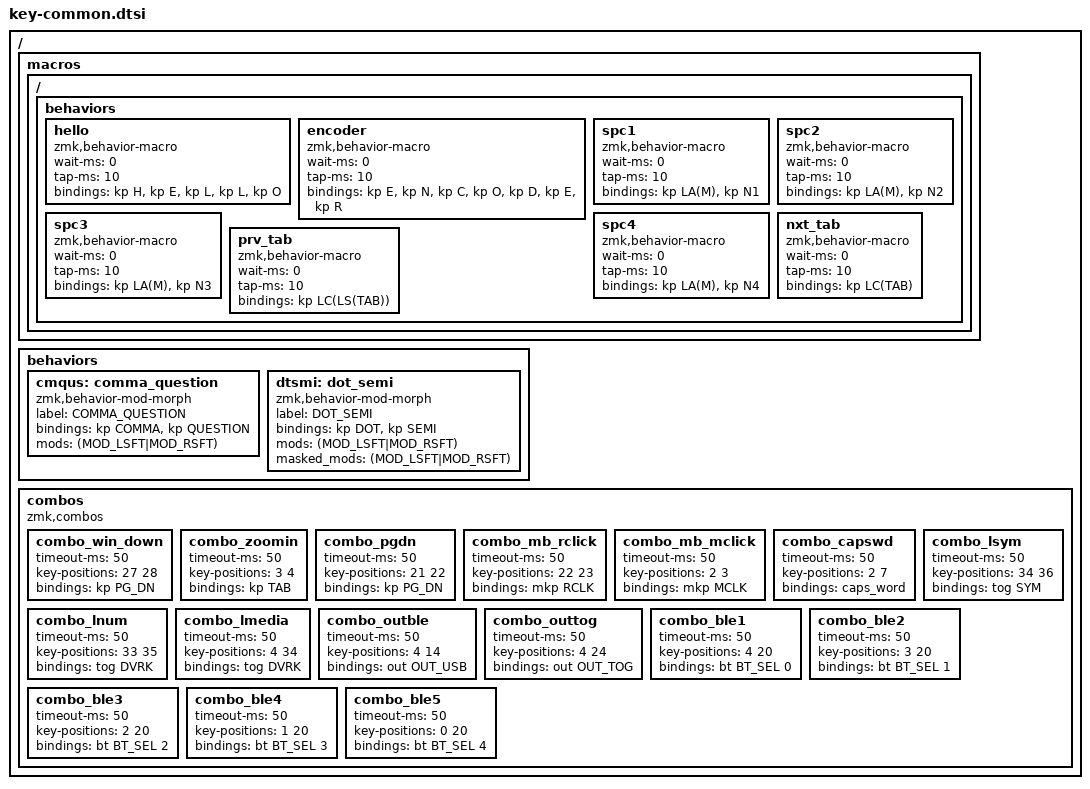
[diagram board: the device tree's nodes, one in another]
/ {
    // macros
    macros {
    ZMK_MACRO(hello,
        wait-ms = <0>;
        tap-ms  = <10>;
        bindings = <&kp H &kp E &kp L &kp L &kp O>;
    )

    ZMK_MACRO(encoder,
        wait-ms = <0>;
        tap-ms  = <10>;
        bindings = <&kp E &kp N &kp C &kp O &kp D &kp E &kp R>;
    )

    ZMK_MACRO(spc1,
        wait-ms = <0>;
        tap-ms  = <10>;
        bindings = <&kp LA(M) &kp N1>;
    )
    
    ZMK_MACRO(spc2,
        wait-ms = <0>;
        tap-ms  = <10>;
        bindings = <&kp LA(M) &kp N2>;
    )
    
    ZMK_MACRO(spc3,
        wait-ms = <0>;
        tap-ms  = <10>;
        bindings = <&kp LA(M) &kp N3>;
    )
   
    ZMK_MACRO(spc4,
        wait-ms = <0>;
        tap-ms  = <10>;
        bindings = <&kp LA(M) &kp N4>;
    )

    ZMK_MACRO(nxt_tab,
        wait-ms = <0>;
        tap-ms  = <10>;
        bindings = <&kp LC(TAB)>;
    )

    ZMK_MACRO(prv_tab,
        wait-ms = <0>;
        tap-ms  = <10>;
        bindings = <&kp LC(LS(TAB))>;
    )
    };

    // custom shift using mod-morph 
    behaviors {
      cmqus: comma_question {
        compatible = "zmk,behavior-mod-morph";
        label = "COMMA_QUESTION";
        #binding-cells = <0>;
        bindings = <&kp COMMA>, <&kp QUESTION>;
        mods = <(MOD_LSFT|MOD_RSFT)>;
      };

      dtsmi: dot_semi {
        compatible = "zmk,behavior-mod-morph";
        label = "DOT_SEMI";
        #binding-cells = <0>;
        bindings = <&kp DOT>, <&kp SEMI>;
        mods = <(MOD_LSFT|MOD_RSFT)>;
        masked_mods = <(MOD_LSFT|MOD_RSFT)>; // don't send shift
      };
    };

    // combos
     combos {
         compatible = "zmk,combos";
      
         combo_win_down {
            timeout-ms = <50>;
            key-positions = <27 28>;
            bindings = <&kp PG_DN>;
        };
        

        combo_zoomin {
            timeout-ms = <50>;
            key-positions = <3 4>;
            bindings = <&kp TAB>;
        };
 
        combo_pgdn {
            timeout-ms = <50>;
            key-positions = <21 22>;
            bindings = <&kp PG_DN>;
        };
 
        combo_mb_rclick {
            timeout-ms = <50>;
            key-positions = <22 23>;
            bindings = <&mkp RCLK>;
        };

         combo_mb_mclick {
            timeout-ms = <50>;
            key-positions = <2 3>;
            bindings = <&mkp MCLK>;
        };
 

        // others
        combo_capswd {
            timeout-ms = <50>;
            key-positions = <2 7>;
            bindings = <&caps_word>;
        };

        combo_lsym {
            timeout-ms = <50>;
            key-positions = <34 36>;
            bindings = <&tog SYM>;
        };

        combo_lnum {
            timeout-ms = <50>;
            key-positions = <33 35>;
            bindings = <&tog DVRK>;
        };

        combo_lmedia {
            timeout-ms = <50>;
            key-positions = <4 34>;
            bindings = <&tog DVRK>;
        };

        // output selection
        combo_outble {
            timeout-ms = <50>;
            key-positions = <4 14>;
            bindings = <&out OUT_USB>;
        };
 
        combo_outtog {
            timeout-ms = <50>;
            key-positions = <4 24>;
            bindings = <&out OUT_TOG>;
        };

        // ble selection
        combo_ble1 {
            timeout-ms = <50>;
            key-positions = <4 20>;
            bindings = <&bt BT_SEL 0>;
        };

        combo_ble2 {
            timeout-ms = <50>;
            key-positions = <3 20>;
            bindings = <&bt BT_SEL 1>;
        };

        combo_ble3 {
            timeout-ms = <50>;
            key-positions = <2 20>;
            bindings = <&bt BT_SEL 2>;
        };

        combo_ble4 {
            timeout-ms = <50>;
            key-positions = <1 20>;
            bindings = <&bt BT_SEL 3>;
        };

        combo_ble5 {
            timeout-ms = <50>;
            key-positions = <0 20>;
            bindings = <&bt BT_SEL 4>;
        };
    };
};
